# ESP32-S31 register map
Vendor: ESPRESSIF SYSTEMS (SHANGHAI) CO., LTD.; Series: ESP32 S-Series; File version: 1
CPU: RV32IMAFC r0p0, little endian, no MPU, FPU, 0 interrupt priority bits
Address unit: 32 bits
Registers are 32-bit, read-write, reset 0x0 unless marked. A register's access mark holds for its fields unless they carry their own. Offsets are from the block's base; [hi:lo] are bit positions.

## GMAC (part 5 of 6) — GMAC Peripheral
Base 0x20350000
0x110C REGISTER67_CHANNEL1RECEIVEDESCRIPTORLISTADDRESSREGISTER — Points the DMA to the start of the Receive Descriptor list
  [31:0] CH1_RDESLA — Start of Receive List This field contains the base address of the first descriptor in the Receive Descriptor list The LSB bits _1:0, 2:0, or 3:0_ for 32bit, 64bit, or 128bit bus width are ignored and internally taken as allzero by the DMA Therefore, these LSB bits are readonly _RO_
0x1110 REGISTER68_CHANNEL1TRANSMITDESCRIPTORLISTADDRESSREGISTER — Points the DMA to the start of the Transmit Descriptor list
  [31:0] CH1_TDESLA — Start of Transmit List This field contains the base address of the first descriptor in the Transmit Descriptor list The LSB bits _1:0, 2:0, 3:0_ for 32bit, 64bit, or 128bit bus width are ignored and are internally taken as allzero by the DMA Therefore, these LSB bits are readonly _RO_
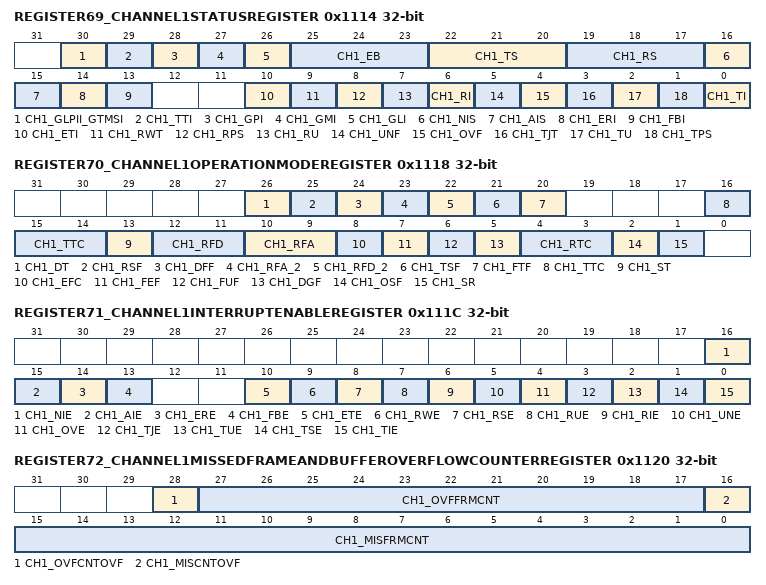
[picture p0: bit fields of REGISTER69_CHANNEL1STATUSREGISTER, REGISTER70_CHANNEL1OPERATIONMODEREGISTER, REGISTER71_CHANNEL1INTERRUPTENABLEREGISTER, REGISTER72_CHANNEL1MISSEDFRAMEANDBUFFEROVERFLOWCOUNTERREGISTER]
0x1114 REGISTER69_CHANNEL1STATUSREGISTER access per field — The Software driver _application_ reads this register during interrupt service routine or polling to determine the status of the DMA Bits 29:26 are reserved for the Channel 1 Status Register
  [30] CH1_GLPII_GTMSI ro — GTMSI: GMAC TMS Interrupt _for Channel 1 and Channel 2_ This bit indicates an interrupt event in the traffic manager and scheduler logic of DWC_gmac To reset this bit, the software must read the corresponding registers _Channel Status Register_ to get the exact cause of the interrupt and clear its source Note: GTMSI status is given only in Channel 1 and Channel 2 DMA register when the AV feature is enabled and corresponding additional transmit channels are present Otherwise, this bit is reserved When this bit is high, the interrupt signal from the MAC _sbd_intr_o_ is high
  [29] CH1_TTI ro — Timestamp Trigger Interrupt This bit indicates an interrupt event in the Timestamp Generator block of the DWC_gmac The software must read the corresponding registers in the DWC_gmac to get the exact cause of the interrupt and clear its source to reset this bit to 1'b0 When this bit is high, the interrupt signal from the DWC_gmac subsystem _sbd_intr_o_ is high This bit is applicable only when the IEEE 1588 Timestamp feature is enabled Otherwise, this bit is reserved
  [28] CH1_GPI ro — GMAC PMT Interrupt This bit indicates an interrupt event in the PMT module of the DWC_gmac The software must read the PMT Control and Status Register in the MAC to get the exact cause of interrupt and clear its source to reset this bit to 1’b0 The interrupt signal from the DWC_gmac subsystem _sbd_intr_o_ is high when this bit is high This bit is applicable only when the Power Management feature is enabled Otherwise, this bit is reserved Note: The GPI and pmt_intr_o interrupts are generated in different clock domains
  [27] CH1_GMI ro — GMAC MMC Interrupt This bit reflects an interrupt event in the MMC module of the DWC_gmac The software must read the corresponding registers in the DWC_gmac to get the exact cause of the interrupt and clear the source of interrupt to make this bit as 1’b0 The interrupt signal from the DWC_gmac subsystem _sbd_intr_o_ is high when this bit is high This bit is applicable only when the MAC Management Counters _MMC_ are enabled Otherwise, this bit is reserved
  [26] CH1_GLI ro — GMAC Line Interface Interrupt When set, this bit reflects any of the following interrupt events in the DWC_gmac interfaces _if present and enabled in your configuration_: PCS _TBI, RTBI, or SGMII_: Link change or autonegotiation complete event SMII or RGMII: Link change event General Purpose Input Status _GPIS_: Any LL or LH event on the gpi_i input ports To identify the exact cause of the interrupt, the software must first read Bit 11 and Bits[2:0] of Register 14 _Interrupt Status Register_ and then to clear the source of interrupt _which also clears the GLI interrupt_, read any of the following corresponding registers: PCS _TBI, RTBI, or SGMII_: Register 49 _AN Status Register_ SMII or RGMII: Register 54 _SGMII/RGMII/SMII Control and Status Register_ General Purpose Input _GPI_: Register 56 _General Purpose IO Register_ The interrupt signal from the DWC_gmac subsystem _sbd_intr_o_ is high when this bit is high
  [25:23] CH1_EB ro — Error Bits This field indicates the type of error that caused a Bus Error, for example, error response on the AHB or AXI interface This field is valid only when Bit 13 _FBI_ is set This field does not generate an interrupt 0 0 0: Error during Rx DMA Write Data Transfer 0 1 1: Error during Tx DMA Read Data Transfer 1 0 0: Error during Rx DMA Descriptor Write Access 1 0 1: Error during Tx DMA Descriptor Write Access 1 1 0: Error during Rx DMA Descriptor Read Access 1 1 1: Error during Tx DMA Descriptor Read Access Note: 001 and 010 are reserved
  [22:20] CH1_TS ro — Transmit Process State This field indicates the Transmit DMA FSM state This field does not generate an interrupt 3’b000: Stopped: Reset or Stop Transmit Command issued 3’b001: Running: Fetching Transmit Transfer Descriptor 3’b010: Running: Waiting for status 3’b011: Running: Reading Data from host memory buffer and queuing it to transmit buffer _Tx FIFO_ 3’b100: TIME_STAMP write state 3’b101: Reserved for future use 3’b110: Suspended: Transmit Descriptor Unavailable or Transmit Buffer Underflow 3’b111: Running: Closing Transmit Descriptor
  [19:17] CH1_RS ro — Receive Process State This field indicates the Receive DMA FSM state This field does not generate an interrupt 3’b000: Stopped: Reset or Stop Receive Command issued 3’b001: Running: Fetching Receive Transfer Descriptor 3’b010: Reserved for future use 3’b011: Running: Waiting for receive packet 3’b100: Suspended: Receive Descriptor Unavailable 3’b101: Running: Closing Receive Descriptor 3’b110: TIME_STAMP write state 3’b111: Running: Transferring the receive packet data from receive buffer to host memory
  [16] CH1_NIS rw — Normal Interrupt Summary Normal Interrupt Summary bit value is the logical OR of the following bits when the corresponding interrupt bits are enabled in Register 7 _Interrupt Enable Register_: Register 5[0]: Transmit Interrupt Register 5[2]: Transmit Buffer Unavailable Register 5[6]: Receive Interrupt Register 5[14]: Early Receive Interrupt Only unmasked bits _interrupts for which interrupt enable is set in Register 7_ affect the Normal Interrupt Summary bit This is a sticky bit and must be cleared _by writing 1 to this bit_ each time a corresponding bit, which causes NIS to be set, is cleared
  [15] CH1_AIS rw — Abnormal Interrupt Summary Abnormal Interrupt Summary bit value is the logical OR of the following when the corresponding interrupt bits are enabled in Register 7 _Interrupt Enable Register_: Register 5[1]: Transmit Process Stopped Register 5[3]: Transmit Jabber Timeout Register 5[4]: Receive FIFO Overflow Register 5[5]: Transmit Underflow Register 5[7]: Receive Buffer Unavailable Register 5[8]: Receive Process Stopped Register 5[9]: Receive Watchdog Timeout Register 5[10]: Early Transmit Interrupt Register 5[13]: Fatal Bus Error Only unmasked bits affect the Abnormal Interrupt Summary bit This is a sticky bit and must be cleared _by writing 1 to this bit_ each time a corresponding bit, which causes AIS to be set, is cleared
  [14] CH1_ERI rw — Early Receive Interrupt This bit indicates that the DMA filled the first data buffer of the packet This bit is cleared when the software writes 1 to this bit or Bit 6 _RI_ of this register is set _whichever occurs earlier_
  [13] CH1_FBI rw — Fatal Bus Error Interrupt This bit indicates that a bus error occurred, as described in Bits [25:23] When this bit is set, the corresponding DMA engine disables all of its bus accesses 12:11 Reserved 00 RO
  [10] CH1_ETI rw — Early Transmit Interrupt This bit indicates that the frame to be transmitted is fully transferred to the MTL Transmit FIFO
  [9] CH1_RWT rw — Receive Watchdog Timeout When set, this bit indicates that the Receive Watchdog Timer expired while receiving the current frame and the current frame is truncated after the watchdog timeout
  [8] CH1_RPS rw — Receive Process Stopped This bit is asserted when the Receive Process enters the Stopped state
  [7] CH1_RU rw — Receive Buffer Unavailable This bit indicates that the host owns the Next Descriptor in the Receive List and the DMA cannot acquire it The Receive Process is suspended To resume processing Receive descriptors, the host should change the ownership of the descriptor and issue a Receive Poll Demand command If no Receive Poll Demand is issued, the Receive Process resumes when the next recognized incoming frame is received This bit is set only when the previous Receive Descriptor is owned by the DMA
  [6] CH1_RI rw — Receive Interrupt This bit indicates that the frame reception is complete When reception is complete, the Bit 31 of RDES1 _Disable Interrupt on Completion_ is reset in the last Descriptor, and the specific frame status information is updated in the descriptor The reception remains in the Running state
  [5] CH1_UNF rw — Transmit Underflow This bit indicates that the Transmit Buffer had an Underflow during frame transmission Transmission is suspended and an Underflow Error TDES0[1] is set
  [4] CH1_OVF rw — Receive Overflow This bit indicates that the Receive Buffer had an Overflow during frame reception If the partial frame is transferred to the application, the overflow status is set in RDES0[11]
  [3] CH1_TJT rw — Transmit Jabber Timeout This bit indicates that the Transmit Jabber Timer expired, which happens when the frame size exceeds 2,048 _10,240 bytes when the Jumbo frame is enabled_ When the Jabber Timeout occurs, the transmission process is aborted and placed in the Stopped state This causes the Transmit Jabber Timeout TDES0[14] flag to assert
  [2] CH1_TU rw — Transmit Buffer Unavailable This bit indicates that the host owns the Next Descriptor in the Transmit List and the DMA cannot acquire it Transmission is suspended Bits[22:20] explain the Transmit Process state transitions To resume processing Transmit descriptors, the host should change the ownership of the descriptor by setting TDES0[31] and then issue a Transmit Poll Demand command
  [1] CH1_TPS rw — Transmit Process Stopped This bit is set when the transmission is stopped
  [0] CH1_TI rw — Transmit Interrupt This bit indicates that the frame transmission is complete When transmission is complete, Bit 31 _OWN_ of TDES0 is reset, and the specific frame status information is updated in the descriptor
0x1118 REGISTER70_CHANNEL1OPERATIONMODEREGISTER — Establishes the Receive and Transmit operating modes and command
  [26] CH1_DT — Disable Dropping of TCP/IP Checksum Error Frames When this bit is set, the MAC does not drop the frames which only have errors detected by the Receive Checksum Offload engine Such frames do not have any errors _including FCS error_ in the Ethernet frame received by the MAC but have errors only in the encapsulated payload When this bit is reset, all error frames are dropped if the FEF bit is reset If the IPC Full Checksum Offload Engine _Type 2_ is disabled, this bit is reserved _RO with value 1'b0_
  [25] CH1_RSF — Receive Store and Forward When this bit is set, the MTL reads a frame from the Rx FIFO only after the complete frame has been written to it, ignoring the RTC bits When this bit is reset, the Rx FIFO operates in the cutthrough mode, subject to the threshold specified by the RTC bits
  [24] CH1_DFF — Disable Flushing of Received Frames When this bit is set, the Rx DMA does not flush any frames because of the unavailability of receive descriptors or buffers as it does normally when this bit is reset _See “Receive Process Suspended” on page 83_ This bit is reserved _and RO_ in the GMACMTL configuration
  [23] CH1_RFA_2 — MSB of Threshold for Activating Flow Control If the DWC_gmac is configured for an Rx FIFO size of 8 KB or more, this bit _when set_ provides additional threshold levels for activating the flow control in both half duplex and fullduplex modes This bit _as Most Significant Bit_, along with the RFA _Bits [10:9]_, gives the following thresholds for activating flow control: 100: Full minus 5 KB, that is, FULL — 5 KB 101: Full minus 6 KB, that is, FULL — 6 KB 110: Full minus 7 KB, that is, FULL — 7 KB 111: Reserved This bit is reserved _and RO_ if the Rx FIFO is 4 KB or less deep
  [22] CH1_RFD_2 — MSB of Threshold for Deactivating Flow Control If the DWC_gmac is configured for Rx FIFO size of 8 KB or more, this bit _when set_ provides additional threshold levels for deactivating the flow control in both halfduplex and fullduplex modes This bit _as Most Significant Bit_ along with the RFD _Bits [12:11]_ gives the following thresholds for deactivating flow control: 100: Full minus 5 KB, that is, FULL — 5 KB 101: Full minus 6 KB, that is, FULL — 6 KB 110: Full minus 7 KB, that is, FULL — 7 KB 111: Reserved This bit is reserved _and RO_ if the Rx FIFO is 4 KB or less deep
  [21] CH1_TSF — Transmit Store and Forward When this bit is set, transmission starts when a full frame resides in the MTL Transmit FIFO When this bit is set, the TTC values specified in Bits [16:14] are ignored This bit should be changed only when the transmission is stopped
  [20] CH1_FTF — Flush Transmit FIFO When this bit is set, the transmit FIFO controller logic is reset to its default values and thus all data in the Tx FIFO is lost or flushed This bit is cleared internally when the flushing operation is complete The Operation Mode register should not be written to until this bit is cleared The data which is already accepted by the MAC transmitter is not flushed It is scheduled for transmission and results in underflow and runt frame transmission Note: The flush operation is complete only when the Tx FIFO is emptied of its contents and all the pending Transmit Status of the transmitted frames are accepted by the host In order to complete this flush operation, the PHY transmit clock _clk_tx_i_ is required to be active 19:17 Reserved 000 RO
  [16:14] CH1_TTC — Transmit Threshold Control These bits control the threshold level of the MTL Transmit FIFO Transmission starts when the frame size within the MTL Transmit FIFO is larger than the threshold In addition, full frames with a length less than the threshold are also transmitted These bits are used only when Bit 21 _TSF_ is reset 000: 64 001: 128 010: 192 011: 256 100: 40 101: 32 110: 24 111: 16
  [13] CH1_ST — Start or Stop Transmission Command When this bit is set, transmission is placed in the Running state, and the DMA checks the Transmit List at the current position for a frame to be transmitted Descriptor acquisition is attempted either from the current position in the list, which is the Transmit List Base Address set by Register 4 _Transmit Descriptor List Address Register_, or from the position retained when transmission was stopped previously If the DMA does not own the current descriptor, transmission enters the Suspended state and Bit 2 _Transmit Buffer Unavailable_ of Register 5 _Status Register_ is set The Start Transmission command is effective only when transmission is stopped If the command is issued before setting Register 4 _Transmit Descriptor List Address Register_, then the DMA behavior is unpredictable When this bit is reset, the transmission process is placed in the Stopped state after completing the transmission of the current frame The Next Descriptor position in the Transmit List is saved, and it becomes the current position when transmission is restarted To change the list address, you need to program Register 4 _Transmit Descriptor List Address Register_ with a new value when this bit is reset The new value is considered when this bit is set again The stop transmission command is effective only when the transmission of the current frame is complete or the transmission is in the Suspended state Note: For information about how to pause the transmission, see “Stopping and Starting Transmission” on page 715
  [12:11] CH1_RFD — Threshold for Deactivating Flow Control _in halfduplex and fullduplex modes_ These bits control the threshold _Filllevel of Rx FIFO_ at which the flow control is deasserted after activation 00: Full minus 1 KB, that is, FULL — 1 KB 01: Full minus 2 KB, that is, FULL — 2 KB 10: Full minus 3 KB, that is, FULL — 3 KB 11: Full minus 4 KB, that is, FULL — 4 KB The deassertion is effective only after flow control is asserted If the Rx FIFO is 8 KB or more, an additional Bit _RFD_2_ is used for more threshold levels as described in Bit 22 These bits are reserved and readonly when the Rx FIFO depth is less than 4 KB Note: For proper flow control, the value programmed in the “RFD_2, RFD” fields should be equal to or more than the value programmed in the “RFA_2, RFA” fields
  [10:9] CH1_RFA — Threshold for Activating Flow Control _in halfduplex and fullduplex modes_ These bits control the threshold _Fill level of Rx FIFO_ at which the flow control is activated 00: Full minus 1 KB, that is, FULL—1KB 01: Full minus 2 KB, that is, FULL—2KB 10: Full minus 3 KB, that is, FULL—3KB 11: Full minus 4 KB, that is, FULL—4KB These values are applicable only to Rx FIFOs of 4 KB or more and when Bit 8 _EFC_ is set high If the Rx FIFO is 8 KB or more, an additional Bit _RFA_2_ is used for more threshold levels as described in Bit 23 These bits are reserved and readonly when the depth of Rx FIFO is less than 4 KB Note: When FIFO size is exactly 4 KB, although the DWC_gmac allows you to program the value of these bits to 11, the software should not program these bits to 2'b11 The value 2'b11 means flow control on FIFO empty condition
  [8] CH1_EFC — Enable HW Flow Control When this bit is set, the flow control signal operation based on the filllevel of Rx FIFO is enabled When reset, the flow control operation is disabled This bit is not used _reserved and always reset_ when the Rx FIFO is less than 4 KB
  [7] CH1_FEF — Forward Error Frames When this bit is reset, the Rx FIFO drops frames with error status _CRC error, collision error, GMII_ER, giant frame, watchdog timeout, or overflow_ However, if the start byte _write_ pointer of a frame is already transferred to the read controller side _in Threshold mode_, then the frame is not dropped In the GMACMTL configuration in which the Frame Length FIFO is also enabled during core configuration, the Rx FIFO drops the error frames if that frame's start byte is not transferred _output_ on the ARI bus When the FEF bit is set, all frames except runt error frames are forwarded to the DMA If the Bit 25 _RSF_ is set and the Rx FIFO overflows when a partial frame is written, then the frame is dropped irrespective of the FEF bit setting However, if the Bit 25 _RSF_ is reset and the Rx FIFO overflows when a partial frame is written, then a partial frame may be forwarded to the DMA Note: When FEF bit is reset, the giant frames are dropped if the giant frame status is given in Rx Status _in Table 86 or Table 823_ in the following configurations: The IP checksum engine _Type 1_ and full checksum offload engine _Type 2_ are not selected The advanced timestamp feature is not selected but the extended status is selected The extended status is available with the following features: L3L4 filter in GMACCORE or GMACMTL configurations Full checksum offload engine _Type 2_ with enhanced descriptor format in the GMACDMA, GMACAHB, or GMACAXI configurations
  [6] CH1_FUF — Forward Undersized Good Frames When set, the Rx FIFO forwards Undersized frames _that is, frames with no Error and length less than 64 bytes_ including padbytes and CRC When reset, the Rx FIFO drops all frames of less than 64 bytes, unless a frame is already transferred because of the lower value of Receive Threshold, for example, RTC = 01
  [5] CH1_DGF — Drop Giant Frames When set, the MAC drops the received giant frames in the Rx FIFO, that is, frames that are larger than the computed giant frame limit When reset, the MAC does not drop the giant frames in the Rx FIFO Note: This bit is available in the following configurations in which the giant frame status is not provided in Rx status and giant frames are not dropped by default: Configurations in which IP Checksum Offload _Type 1_ is selected in Rx Configurations in which the IPC Full Checksum Offload Engine _Type 2_ is selected in Rx with normal descriptor format Configurations in which the Advanced Timestamp feature is selected In all other configurations, this bit is not used _reserved and always reset_
  [4:3] CH1_RTC — Receive Threshold Control These two bits control the threshold level of the MTL Receive FIFO Transfer _request_ to DMA starts when the frame size within the MTL Receive FIFO is larger than the threshold In addition, full frames with length less than the threshold are automatically transferred The value of 11 is not applicable if the configured Receive FIFO size is 128 bytes These bits are valid only when the RSF bit is zero, and are ignored when the RSF bit is set to 1 00: 64 01: 32 10: 96 11: 128
  [2] CH1_OSF — Operate on Second Frame When this bit is set, it instructs the DMA to process the second frame of the Transmit data even before the status for the first frame is obtained
  [1] CH1_SR — Start or Stop Receive When this bit is set, the Receive process is placed in the Running state The DMA attempts to acquire the descriptor from the Receive list and processes the incoming frames The descriptor acquisition is attempted from the current position in the list, which is the address set by the Register 3 _Receive Descriptor List Address Register_ or the position retained when the Receive process was previously stopped If the DMA does not own the descriptor, reception is suspended and Bit 7 _Receive Buffer Unavailable_ of Register 5 _Status Register_ is set The Start Receive command is effective only when the reception has stopped If the command is issued before setting Register 3 _Receive Descriptor List Address Register_, the DMA behavior is unpredictable When this bit is cleared, the Rx DMA operation is stopped after the transfer of the current frame The next descriptor position in the Receive list is saved and becomes the current position after the Receive process is restarted The Stop Receive command is effective only when the Receive process is in either the Running _waiting for receive packet_ or in the Suspended state Note: For information about how to pause the transmission, see “Stopping and Starting Transmission” on page 715
0x111C REGISTER71_CHANNEL1INTERRUPTENABLEREGISTER — Enables the interrupts reported by the Status Register
  [16] CH1_NIE — Normal Interrupt Summary Enable When this bit is set, normal interrupt summary is enabled When this bit is reset, normal interrupt summary is disabled This bit enables the following interrupts in Register 5 _Status Register_: Register 5[0]: Transmit Interrupt Register 5[2]: Transmit Buffer Unavailable Register 5[6]: Receive Interrupt Register 5[14]: Early Receive Interrupt
  [15] CH1_AIE — Abnormal Interrupt Summary Enable When this bit is set, abnormal interrupt summary is enabled When this bit is reset, the abnormal interrupt summary is disabled This bit enables the following interrupts in Register 5 _Status Register_: Register 5[1]: Transmit Process Stopped Register 5[3]: Transmit Jabber Timeout Register 5[4]: Receive Overflow Register 5[5]: Transmit Underflow Register 5[7]: Receive Buffer Unavailable Register 5[8]: Receive Process Stopped Register 5[9]: Receive Watchdog Timeout Register 5[10]: Early Transmit Interrupt Register 5[13]: Fatal Bus Error
  [14] CH1_ERE — Early Receive Interrupt Enable When this bit is set with Normal Interrupt Summary Enable _Bit 16_, the Early Receive Interrupt is enabled When this bit is reset, the Early Receive Interrupt is disabled
  [13] CH1_FBE — Fatal Bus Error Enable When this bit is set with Abnormal Interrupt Summary Enable _Bit 15_, the Fatal Bus Error Interrupt is enabled When this bit is reset, the Fatal Bus Error Enable Interrupt is disabled 12:11 Reserved 00 RO
  [10] CH1_ETE — Early Transmit Interrupt Enable When this bit is set with an Abnormal Interrupt Summary Enable _Bit 15_, the Early Transmit Interrupt is enabled When this bit is reset, the Early Transmit Interrupt is disabled
  [9] CH1_RWE — Receive Watchdog Timeout Enable When this bit is set with Abnormal Interrupt Summary Enable _Bit 15_, the Receive Watchdog Timeout Interrupt is enabled When this bit is reset, the Receive Watchdog Timeout Interrupt is disabled
  [8] CH1_RSE — Receive Stopped Enable When this bit is set with Abnormal Interrupt Summary Enable _Bit 15_, the Receive Stopped Interrupt is enabled When this bit is reset, the Receive Stopped Interrupt is disabled
  [7] CH1_RUE — Receive Buffer Unavailable Enable When this bit is set with Abnormal Interrupt Summary Enable _Bit 15_, the Receive Buffer Unavailable Interrupt is enabled When this bit is reset, the Receive Buffer Unavailable Interrupt is disabled
  [6] CH1_RIE — Receive Interrupt Enable When this bit is set with Normal Interrupt Summary Enable _Bit 16_, the Receive Interrupt is enabled When this bit is reset, the Receive Interrupt is disabled
  [5] CH1_UNE — Underflow Interrupt Enable When this bit is set with Abnormal Interrupt Summary Enable _Bit 15_, the Transmit Underflow Interrupt is enabled When this bit is reset, the Underflow Interrupt is disabled
  [4] CH1_OVE — Overflow Interrupt Enable When this bit is set with Abnormal Interrupt Summary Enable _Bit 15_, the Receive Overflow Interrupt is enabled When this bit is reset, the Overflow Interrupt is disabled
  [3] CH1_TJE — Transmit Jabber Timeout Enable When this bit is set with Abnormal Interrupt Summary Enable _Bit 15_, the Transmit Jabber Timeout Interrupt is enabled When this bit is reset, the Transmit Jabber Timeout Interrupt is disabled
  [2] CH1_TUE — Transmit Buffer Unavailable Enable When this bit is set with Normal Interrupt Summary Enable _Bit 16_, the Transmit Buffer Unavailable Interrupt is enabled When this bit is reset, the Transmit Buffer Unavailable Interrupt is disabled
  [1] CH1_TSE — Transmit Stopped Enable When this bit is set with Abnormal Interrupt Summary Enable _Bit 15_, the Transmission Stopped Interrupt is enabled When this bit is reset, the Transmission Stopped Interrupt is disabled
  [0] CH1_TIE — Transmit Interrupt Enable When this bit is set with Normal Interrupt Summary Enable _Bit 16_, the Transmit Interrupt is enabled When this bit is reset, the Transmit Interrupt is disabled The sbd_intr_o interrupt is generated as shown in Figure 61 It is asserted only when the TTI, GPI, GMI, GLI, or GLPII bit of the DMA Status register is asserted, or when the NIS or AIS Status bit is asserted and the corresponding Interrupt Enable bits _NIE or AIE_ are enabled
0x1120 REGISTER72_CHANNEL1MISSEDFRAMEANDBUFFEROVERFLOWCOUNTERREGISTER — Contains the counters for discarded frames because no host Receive Descriptor was available, and discarded frames because of Receive FIFO Overflow
  [28] CH1_OVFCNTOVF — Overflow Bit for FIFO Overflow Counter This bit is set every time the Overflow Frame Counter _Bits[27:17]_ overflows, that is, the Rx FIFO overflows with the overflow frame counter at maximum value In such a scenario, the overflow frame counter is reset to allzeros and this bit indicates that the rollover happened
  [27:17] CH1_OVFFRMCNT — Overflow Frame Counter This field indicates the number of frames missed by the application This counter is incremented each time the MTL FIFO overflows The counter is cleared when this register is read with mci_be_i[2] at 1’b1
  [16] CH1_MISCNTOVF — Overflow Bit for Missed Frame Counter This bit is set every time Missed Frame Counter _Bits[15:0]_ overflows, that is, the DMA discards an incoming frame because of the Host Receive Buffer being unavailable with the missed frame counter at maximum value In such a scenario, the Missed frame counter is reset to allzeros and this bit indicates that the rollover happened
  [15:0] CH1_MISFRMCNT — Missed Frame Counter This field indicates the number of frames missed by the controller because of the Host Receive Buffer being unavailable This counter is incremented each time the DMA discards an incoming frame The counter is cleared when this register is read with mci_be_i[0] at 1’b1
0x1124 REGISTER73_CHANNEL1RECEIVEINTERRUPTWATCHDOGTIMERREGISTER — Watchdog timeout for Receive Interrupt _RI_ from DMA
  [7:0] CH1_RIWT — RI Watchdog Timer Count This bit indicates the number of system clock cycles multiplied by 256 for which the watchdog timer is set The watchdog timer gets triggered with the programmed value after the Rx DMA completes the transfer of a frame for which the RI status bit is not set because of the setting in the corresponding descriptor RDES1[31] When the watchdog timer runs out, the RI bit is set and the timer is stopped The watchdog timer is reset when the RI bit is set high because of automatic setting of RI as per RDES1[31] of any received frame
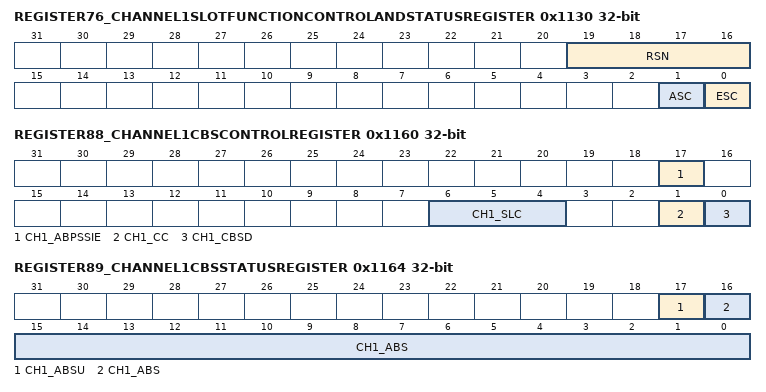
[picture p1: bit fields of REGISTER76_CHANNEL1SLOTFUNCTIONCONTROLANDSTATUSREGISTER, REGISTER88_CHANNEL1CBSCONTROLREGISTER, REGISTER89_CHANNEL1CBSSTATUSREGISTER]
0x1130 REGISTER76_CHANNEL1SLOTFUNCTIONCONTROLANDSTATUSREGISTER access per field — Contains the control bits for slot function and its status for Channel 1 transmit path
  [19:16] RSN ro — Reference Slot Number This field gives the current value of the reference slot number in DMA used for comparison checking
  [1] ASC rw — Advance Slot Check When set, this bit enables the DMA to fetch the data from the buffer when the slot number _SLOTNUM_ programmed in the transmit descriptor is: equal to the reference slot number given in Bits [19:16] or ahead of the reference slot number by up to two slots This bit is applicable only when Bit 0 _ESC_ is set
  [0] ESC rw — Enable Slot Comparison When set, this bit enables the checking of the slot numbers, programmed in the transmit descriptor, with the current reference given in Bits [19:16] The DMA fetches the data from the corresponding buffer only when the slot number is equal to the reference slot number or is ahead of the reference slot number by one slot When reset, this bit disables the checking of the slot numbers The DMA fetches the data immediately after the descriptor is processed
0x1148 REGISTER82_CHANNEL1CURRENTHOSTTRANSMITDESCRIPTORREGISTER ro — Points to the start of current Transmit Descriptor read by the DMA
  [31:0] CH1_CURTDESAPTR — Host Transmit Descriptor Address Pointer
0x114C REGISTER83_CHANNEL1CURRENTHOSTRECEIVEDESCRIPTORREGISTER ro — Points to the start of current Receive Descriptor read by the DMA
  [31:0] CH1_CURRDESAPTR — Host Receive Descriptor Address Pointer
0x1150 REGISTER84_CHANNEL1CURRENTHOSTTRANSMITBUFFERADDRESSREGISTER ro — Points to the current Transmit Buffer address read by the DMA
  [31:0] CH1_CURTBUFAPTR — Host Transmit Buffer Address Pointer
0x1154 REGISTER85_CHANNEL1CURRENTHOSTRECEIVEBUFFERADDRESSREGISTER ro — Points to the current Receive Buffer address read by the DMA
  [31:0] CH1_CURRBUFAPTR — Host Receive Buffer Address Pointer
0x1160 REGISTER88_CHANNEL1CBSCONTROLREGISTER — Controls the Channel 1 credit shaping operation on the transmit path
  [17] CH1_ABPSSIE — Average Bits Per Slot Interrupt Enable When this bit is set, the MAC asserts an interrupt _sbd_intr_o or mci_intr_o_ when the average bits per slot status is updated _Bit 17 _ABSU_ in Register 89_ for Channel 1 When this bit is cleared, interrupt is not asserted for such an event
  [6:4] CH1_SLC — Slot Count The software can program the number of slots _of duration 125 microsec_ over which the average transmitted bits per slot _provided in the CBS Status register_ need to be computed for Channel 1 when the creditbased shaper algorithm is enabled The encoding is as follows: 3'b000: 1 Slot 3'b001: 2 Slots 3'b010: 4 Slots 3'b011: 8 Slots 3'b100: 16 Slots 3'b1013'b111: Reserved
  [1] CH1_CC — Credit Control When reset, the accumulated credit parameter in the creditbased shaper algorithm logic is set to zero when there is positive credit and no frame to transmit in Channel 1 When there is no frame waiting in Channel 1 and other channel is transmitting, no credit is accumulated When set, the accumulated credit parameter in the creditbased shaper algorithm logic is not reset to zero when there is positive credit and no frame to transmit in Channel 1 The credit accumulates even when there is no frame waiting in Channel 1 and another channel is transmitting
  [0] CH1_CBSD — CreditBased Shaper Disable When set, the MAC disables the creditbased shaper algorithm for Channel 1 traffic and makes the traffic management algorithm to strict priority for Channel 1 over Channel 0 When reset, the creditbased shaper algorithm schedules the traffic in Channel 1 for transmission
0x1164 REGISTER89_CHANNEL1CBSSTATUSREGISTER ro — Provides the average traffic transmitted in Channel 1
  [17] CH1_ABSU — ABS Updated When set, this bit indicates that the MAC has updated the ABS value This bit is cleared when the application reads the ABS value
  [16:0] CH1_ABS — Average Bits per Slot This field contains the average transmitted bits per slot This field is computed over programmed number of slots _SLC bits in the CBS Control Register_ for Channel 1 traffic The maximum value is 0x30D4 for 100 Mbps and 0x1E848 for 1000 Mbps
0x1168 REGISTER90_CHANNEL1IDLESLOPECREDITREGISTER — Contains the idleSlope credit value required for the creditbased shaper algorithm for Channel 1
  [13:0] CH1_ISC — idleSlopeCredit This field contains the idleSlopeCredit value required for the creditbased shaper algorithm for Channel 1 This is the rate of change of credit in bits per cycle _40ns and 8ns for 100 Mbps and 1000 Mbps respectively_ when the credit is increasing The software should program this field with computed credit in bits per cycle scaled by 1024 The maximum value is portTransmitRate, that is, 0x2000 in 1000 Mbps mode and 0x1000 in 100 Mbps mode
0x116C REGISTER91_CHANNEL1SENDSLOPECREDITREGISTER — Contains the sendSlope credit value required for the creditbased shaper algorithm for Channel 1
  [13:0] CH1_SSC — sendSlopeCredit This field contains the sendSlopeCredit value required for creditbased shaper algorithm for Channel 1 This is the rate of change of credit in bits per cycle _40ns and 8ns for 100 Mbps and 1000 Mbps respectively_ when the credit is decreasing The software should program this field with computed credit in bits per cycle scaled by 1024 The maximum value is portTransmitRate, that is, 0x2000 in 1000 Mbps mode and 0x1000 in 100 Mbps mode This field should be programmed with absolute sendSlopeCredit value The creditbased shaper logic subtracts it from the accumulated credit when Channel 1 is selected for transmission
0x1170 REGISTER92_CHANNEL1HICREDITREGISTER — Contains the hiCredit value required for the creditbased shaper algorithm for Channel 1
  [28:0] CH1_HC — hiCredit This field contains the hiCredit value required for the creditbased shaper algorithm for Channel 1 This is the maximum value that can be accumulated in the credit parameter This is specified in bits scaled by 1,024 The maximum value is maxInterferenceSize, that is, besteffort maximum frame size which is 16,384 bytes or 131,072 bits The value to be specified is 131,072 * 1,024 = 134,217,728 or 0x0800_0000
0x1174 REGISTER93_CHANNEL1LOCREDITREGISTER reset 0x1FFFFFFF — Contains the loCredit value required for the creditbased shaper algorithm for Channel 1
  [28:0] CH1_LC — loCredit This field contains the loCredit value required for the creditbased shaper algorithm for Channel 1 This is the minimum value that can be accumulated in the credit parameter This is specified in bits scaled by 1,024 The maximum value is maxInterferenceSize, that is, besteffort maximum frame size which is 16,384 bytes or 131,072 bits The value to be specified is 131,072 * 1,024 = 134,217,728 or 0x0800_0000 The programmed value is 2's complement _negative number_, that is, 0xF800_0000
